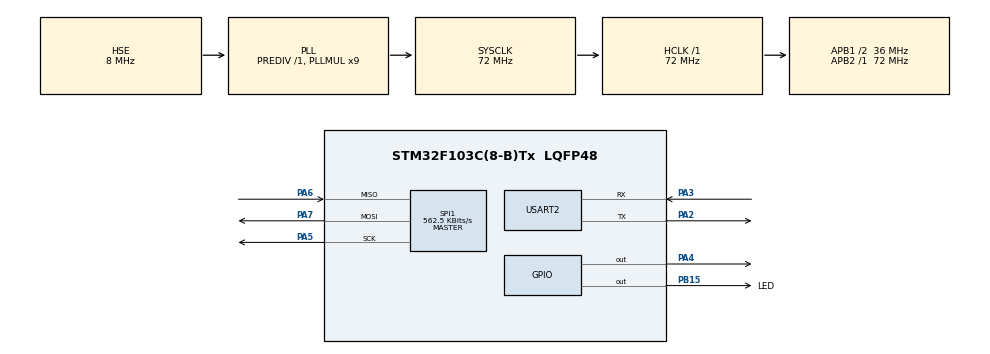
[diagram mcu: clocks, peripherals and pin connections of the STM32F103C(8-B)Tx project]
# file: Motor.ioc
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Dma.Request0=SPI1_TX
Dma.Request1=SPI1_RX
Dma.SPI1_RX.1.Direction=DMA_PERIPH_TO_MEMORY
Dma.SPI1_RX.1.Instance=DMA1_Channel2
Dma.SPI1_RX.1.MemDataAlignment=DMA_MDATAALIGN_BYTE
Dma.SPI1_RX.1.MemInc=DMA_MINC_ENABLE
Dma.SPI1_RX.1.Mode=DMA_NORMAL
Dma.SPI1_RX.1.PeriphDataAlignment=DMA_PDATAALIGN_BYTE
Dma.SPI1_RX.1.PeriphInc=DMA_PINC_DISABLE
Dma.SPI1_RX.1.Priority=DMA_PRIORITY_LOW
Dma.SPI1_TX.0.Direction=DMA_MEMORY_TO_PERIPH
Dma.SPI1_TX.0.Instance=DMA1_Channel3
Dma.SPI1_TX.0.MemDataAlignment=DMA_MDATAALIGN_BYTE
Dma.SPI1_TX.0.MemInc=DMA_MINC_ENABLE
Dma.SPI1_TX.0.Mode=DMA_NORMAL
Dma.SPI1_TX.0.PeriphDataAlignment=DMA_PDATAALIGN_BYTE
Dma.SPI1_TX.0.PeriphInc=DMA_PINC_DISABLE
Dma.SPI1_TX.0.Priority=DMA_PRIORITY_LOW
Mcu.Family=STM32F1
Mcu.Name=STM32F103C(8-B)Tx
Mcu.Package=LQFP48
Mcu.UserConstants=SpeedCalFreq,MotorSpeedCalFreq
NVIC.DMA1_Channel2_IRQn=true\:0\:0\:false\:false\:true\:false\:true\:true
NVIC.DMA1_Channel3_IRQn=true\:0\:0\:false\:false\:true\:false\:true\:true
NVIC.PriorityGroup=NVIC_PRIORITYGROUP_4
NVIC.TIM3_IRQn=true\:0\:0\:false\:false\:true\:true\:true\:true
PA13.Mode=Serial_Wire
PA13.Signal=SYS_JTMS-SWDIO
PA14.Mode=Serial_Wire
PA14.Signal=SYS_JTCK-SWCLK
PA2.Mode=Asynchronous
PA2.Signal=USART2_TX
PA3.Mode=Asynchronous
PA3.Signal=USART2_RX
PA4.PinState=GPIO_PIN_SET
PA4.Signal=GPIO_Output
PA5.Mode=Full_Duplex_Master
PA5.Signal=SPI1_SCK
PA6.Mode=Full_Duplex_Master
PA6.Signal=SPI1_MISO
PA7.Mode=Full_Duplex_Master
PA7.Signal=SPI1_MOSI
PB15.GPIO_Label=LED
PB15.Signal=GPIO_Output
PD0-OSC_IN.Mode=HSE-External-Oscillator
PD0-OSC_IN.Signal=RCC_OSC_IN
PD1-OSC_OUT.Mode=HSE-External-Oscillator
PD1-OSC_OUT.Signal=RCC_OSC_OUT
ProjectManager.HeapSize=0x200
ProjectManager.StackSize=0x400
ProjectManager.TargetToolchain=MDK-ARM V5
RCC.AHBFreq_Value=72000000
RCC.APB1CLKDivider=RCC_HCLK_DIV2
RCC.APB1Freq_Value=36000000
RCC.APB1TimFreq_Value=72000000
RCC.APB2Freq_Value=72000000
RCC.APB2TimFreq_Value=72000000
RCC.HCLKFreq_Value=72000000
RCC.PLLMUL=RCC_PLL_MUL9
RCC.PLLSourceVirtual=RCC_PLLSOURCE_HSE
RCC.SYSCLKFreq_VALUE=72000000
RCC.SYSCLKSource=RCC_SYSCLKSOURCE_PLLCLK
RCC.USBFreq_Value=72000000
SPI1.BaudRatePrescaler=SPI_BAUDRATEPRESCALER_128
SPI1.CLKPhase=SPI_PHASE_2EDGE
SPI1.CalculateBaudRate=562.5 KBits/s
SPI1.Direction=SPI_DIRECTION_2LINES
SPI1.Mode=SPI_MODE_MASTER
SPI1.VirtualType=VM_MASTER
STMicroelectronics.X-CUBE-ALGOBUILD.1.4.0.LibraryCcDSPOoLibraryJjDSPOoLibrary=true
TIM3.Period=SpeedCalFreq
TIM3.Prescaler=72-1
USART2.VirtualMode=VM_ASYNC
VP_STMicroelectronics.X-CUBE-ALGOBUILD_VS_DSPOoLibraryJjLibrary_1.4.0_1.4.0.Mode=DSPOoLibraryJjLibrary
VP_TIM3_VS_ClockSourceINT.Mode=Internal
board=custom

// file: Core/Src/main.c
/* USER CODE BEGIN Header */
/**
  ******************************************************************************
  * @file           : main.c
  * @brief          : Main program body
  ******************************************************************************
  * @attention
  *
  * <h2><center>&copy; Copyright (c) 2025 STMicroelectronics.
  * All rights reserved.</center></h2>
  *
  * This software component is licensed by ST under Ultimate Liberty license
  * SLA0044, the "License"; You may not use this file except in compliance with
  * the License. You may obtain a copy of the License at:
  *                             www.st.com/SLA0044
  *
  ******************************************************************************
  */

/* USER CODE END Header */
#include "main.h"
#include "dma.h"
#include "spi.h"
#include "tim.h"
#include "usart.h"
#include "gpio.h"

void SystemClock_Config(void);

/* USER CODE BEGIN 0 */
extern uint8_t SpiRxBuff[3];
extern uint8_t mt6701_rx_data[3] ;
/* USER CODE END 0 */

int main(void)
{

  /* MCU Configuration--------------------------------------------------------*/

  /* Reset of all peripherals, Initializes the Flash interface and the Systick. */
  HAL_Init();

  /* Configure the system clock */
  SystemClock_Config();

  /* Initialize all configured peripherals */
  MX_GPIO_Init();
  MX_DMA_Init();
  MX_SPI1_Init();
  MX_USART2_UART_Init();
  MX_TIM3_Init();

  /* Infinite loop */
  /* USER CODE BEGIN WHILE */
	HAL_GPIO_WritePin(GPIOA, GPIO_PIN_4, GPIO_PIN_RESET);
	HAL_SPI_TransmitReceive_DMA(&hspi1,SpiRxBuff,SpiRxBuff,3);
	HAL_Delay(10); // ��ʱһ�ᣬ�ýǶȱ�������ֵ����ȻĬ�ϽǶ���0
  while (1)
  {
		HAL_Delay(500);
		HAL_GPIO_TogglePin(LED_GPIO_Port,LED_Pin);
    /* USER CODE END WHILE */

  }
}

void SystemClock_Config(void)
{
  RCC_OscInitTypeDef RCC_OscInitStruct = {0};
  RCC_ClkInitTypeDef RCC_ClkInitStruct = {0};

  /** Initializes the RCC Oscillators according to the specified parameters
  * in the RCC_OscInitTypeDef structure.
  */
  RCC_OscInitStruct.OscillatorType = RCC_OSCILLATORTYPE_HSE;
  RCC_OscInitStruct.HSEState = RCC_HSE_ON;
  RCC_OscInitStruct.HSEPredivValue = RCC_HSE_PREDIV_DIV1;
  RCC_OscInitStruct.HSIState = RCC_HSI_ON;
  RCC_OscInitStruct.PLL.PLLState = RCC_PLL_ON;
  RCC_OscInitStruct.PLL.PLLSource = RCC_PLLSOURCE_HSE;
  RCC_OscInitStruct.PLL.PLLMUL = RCC_PLL_MUL9;
  if (HAL_RCC_OscConfig(&RCC_OscInitStruct) != HAL_OK)
  {
    Error_Handler();
  }

  /** Initializes the CPU, AHB and APB buses clocks
  */
  RCC_ClkInitStruct.ClockType = RCC_CLOCKTYPE_HCLK|RCC_CLOCKTYPE_SYSCLK
                              |RCC_CLOCKTYPE_PCLK1|RCC_CLOCKTYPE_PCLK2;
  RCC_ClkInitStruct.SYSCLKSource = RCC_SYSCLKSOURCE_PLLCLK;
  RCC_ClkInitStruct.AHBCLKDivider = RCC_SYSCLK_DIV1;
  RCC_ClkInitStruct.APB1CLKDivider = RCC_HCLK_DIV2;
  RCC_ClkInitStruct.APB2CLKDivider = RCC_HCLK_DIV1;

  if (HAL_RCC_ClockConfig(&RCC_ClkInitStruct, FLASH_LATENCY_2) != HAL_OK)
  {
    Error_Handler();
  }
}

void Error_Handler(void)
{
  __disable_irq();
  while (1)
  {
  }
}
